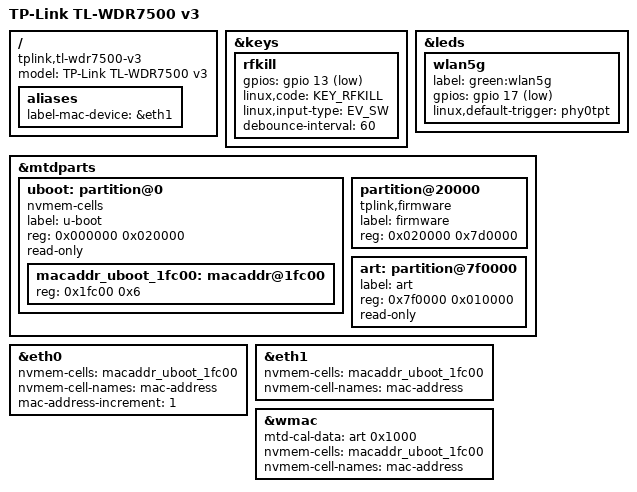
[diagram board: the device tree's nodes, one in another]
// SPDX-License-Identifier: GPL-2.0-or-later OR MIT

#include "qca9558_tplink_archer-c.dtsi"

/ {
	compatible = "tplink,tl-wdr7500-v3", "qca,qca9558";
	model = "TP-Link TL-WDR7500 v3";

	aliases {
		label-mac-device = &eth1;
	};
};

&keys {
	rfkill {
		gpios = <&gpio 13 GPIO_ACTIVE_LOW>;
		linux,code = <KEY_RFKILL>;
		linux,input-type = <EV_SW>;
		debounce-interval = <60>;
	};
};

&leds {
	wlan5g {
		label = "green:wlan5g";
		gpios = <&gpio 17 GPIO_ACTIVE_LOW>;
		linux,default-trigger = "phy0tpt";
	};
};

&mtdparts {
	uboot: partition@0 {
		label = "u-boot";
		reg = <0x000000 0x020000>;
		read-only;
	};

	partition@20000 {
		label = "firmware";
		compatible = "tplink,firmware";
		reg = <0x020000 0x7d0000>;
	};

	art: partition@7f0000 {
		label = "art";
		reg = <0x7f0000 0x010000>;
		read-only;
	};
};

&eth0 {
	nvmem-cells = <&macaddr_uboot_1fc00>;
	nvmem-cell-names = "mac-address";
	mac-address-increment = <1>;
};

&eth1 {
	nvmem-cells = <&macaddr_uboot_1fc00>;
	nvmem-cell-names = "mac-address";
};

&wmac {
	mtd-cal-data = <&art 0x1000>;

	nvmem-cells = <&macaddr_uboot_1fc00>;
	nvmem-cell-names = "mac-address";
};

&uboot {
	compatible = "nvmem-cells";
	#address-cells = <1>;
	#size-cells = <1>;

	macaddr_uboot_1fc00: macaddr@1fc00 {
		reg = <0x1fc00 0x6>;
	};
};
